# host_xip_secure register map
Vendor: Texas Instruments
Peripheral module from a debugger description file (folder CC35X1).
Registers are 32-bit, access per field, reset 0x0 unless marked. A register's access mark holds for its fields unless they carry their own. Offsets are as the file gives them; lines under a group give offsets from that group; [hi:lo] are bit positions; {n}, {i} and the like mark numbered series; 'fields as' and 'values as' point back to an identical list; <NAME> marks a mode.

## host_xip_secure
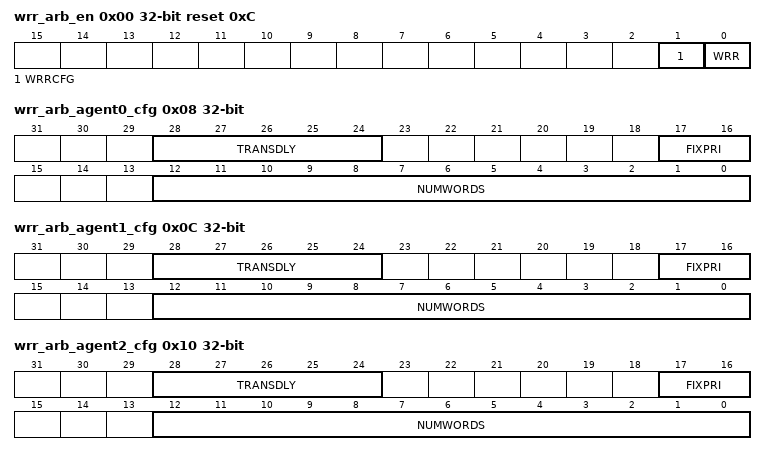
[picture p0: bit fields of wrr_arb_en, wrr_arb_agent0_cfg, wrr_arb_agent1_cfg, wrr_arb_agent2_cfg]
0x00 wrr_arb_en reset 0xC (reset mask 0xFFFFFFFC) — WRR Arbiter Enable
  [1] WRRCFG rw — WRR ARB POLICY RR: 0 - Fixed Priority 1 - Round Robin (Default)
  [0] WRR rw — 0 - Disabled, use SIE-200 arbitration logic. 1 - Enable, use wrapper arbitration logic.
0x08 wrr_arb_agent0_cfg reset not defined — WRR Arbiter - Agent 0 Configuration
  [28:24] TRANSDLY rw — Number of cycle before starting to serve next agent in line. Up to 32 cycles.
  [17:16] FIXPRI rw — For Fixed Priority: 0 - Highest. 1 - Medium. 2 - Lowest (default).
  [12:0] NUMWORDS rw — Number of words to be served in each arbitration grant. Up to 8,192 words (32KB). Value must be > 0.
0x0C wrr_arb_agent1_cfg reset not defined — WRR Arbiter - Agent 1 Configuration
  [28:24] TRANSDLY rw — Number of cycle before starting to serve next agent in line. Up to 32 cycles.
  [17:16] FIXPRI rw — For Fixed Priority: 0 - Highest. 1 - Medium (default). 2 - Lowest.
  [12:0] NUMWORDS rw — Number of words to be served in each arbitration grant. Up to 8,192 words (32KB). Value must be > 0.
0x10 wrr_arb_agent2_cfg reset not defined — WRR Arbiter - Agent 2 Configuration
  [28:24] TRANSDLY rw — Number of cycle before starting to serve next agent in line. Up to 32 cycles.
  [17:16] FIXPRI rw — For Fixed Priority: 0 - Highest (default). 1 - Medium. 2 - Lowest.
  [12:0] NUMWORDS rw — Number of words to be served in each arbitration grant. Up to 8,192 words (32KB). Value must be > 0.
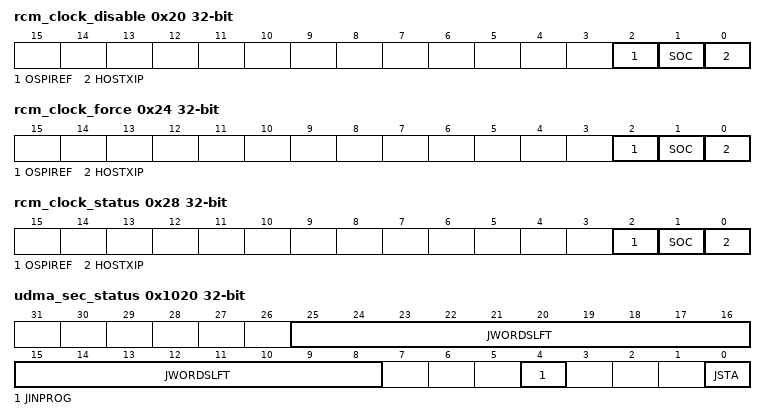
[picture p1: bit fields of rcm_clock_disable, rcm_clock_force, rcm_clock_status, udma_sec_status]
0x20 rcm_clock_disable — Disable clocks using HOST_XIP_RCM Module
  [2] OSPIREF rw — OSPI REF CLK SW DISABLE: 1 - Clock is permanent blocked (not depended on clk_req input) 0 - (default) - Clock is not blocked, but gated with clk_req input port
  [1] SOC rw — SOC CLK SW DISABLE: 1 - Clock is permanent blocked (not depended on clk_req input) 0 - (default) - Clock is not blocked, but gated with clk_req input port
  [0] HOSTXIP rw — HOST_XIP CLK SW DISABLE: 1 - Clock is permanent blocked (not depended on clk_req input) 0 - (default) - Clock is not blocked, but gated with clk_req input port
0x24 rcm_clock_force — Force clocks using HOST_XIP_RCM Module
  [2] OSPIREF rw — OSPI REF CLK SW FORCE: 1 - Force clk (even if sw_disable_clk is 1 or clk_req is 0) 0 - Clock is not forced, but gated with clk_req input port
  [1] SOC rw — SOC CLK SW FORCE: 1 - Force clk (even if sw_disable_clk is 1 or clk_req is 0) 0 - Clock is not forced, but gated with clk_req input port
  [0] HOSTXIP rw — HOST_XIP CLK SW FORCE: 1 - Force clk (even if sw_disable_clk is 1 or clk_req is 0) 0 - Clock is not forced, but gated with clk_req input port
0x28 rcm_clock_status ro — (ICG) Clock Status from HOST_XIP_RCM Module
  [2] OSPIREF — 1 - Force clk (even if sw_disable_clk is 1 or clk_req is 0) 0 - Clock is not forced, but gated with clk_req input port
  [1] SOC — 1 - Force clk (even if sw_disable_clk is 1 or clk_req is 0) 0 - Clock is not forced, but gated with clk_req input port
  [0] HOSTXIP — 1 - Force clk (even if sw_disable_clk is 1 or clk_req is 0) 0 - Clock is not forced, but gated with clk_req input port
0x1000 udma_sec_src_addr_cfg rw — uDMA source address for secured read master. Must be Word aligned.
  [31:0] JSRCADDR — DMA SEC JOB SRC ADDR: Specifies source address for secured read master. Source address must comply with bit.26 to enable Sec/Non-Sec accesses, otherwise transactions will be blocked.
0x1004 udma_sec_dst_addr_cfg rw — uDMA destination address for secured write master. Must be Word aligned.
  [31:0] JDESTADDR — DMA SEC JOB DST ADDR: Specifies destination address for secured write master. Destination address must comply with bit.26 to enable Sec/Non-Sec accesses, otherwise transactions will be blocked.
0x1008 udma_sec_length_cfg — uDMA secured job Length
  [17:0] JLEN rw — DMA SEC JOB LENGTH: Resolution - 1 Word Maximum configurable job size - 1 Mega byte (256K Words). (Maximum available size in MEMSS is 1MB).
0x100C udma_sec_mode_cfg — uDMA Direction
  [0] JDIR rw — DMA SEC JOB MODE: 0 - Data movement from External memory to Internal memory. 1 - Data movement from Internal memory to External memory.
0x1010 udma_sec_start — uDMA secured job kick
  [0] JSTART wo — DMA SEC JOB START WRCL: Start command for uDMA to start working on secured configured job.
0x1014 udma_sec_clear — uDMA secured job abort
  [0] JCLR wo — DMA SEC JOB CLEAR WRCL: Clear command for uDMA to stop working and clear configuration.
0x1020 udma_sec_status ro — uDMA secured Status bits
  [25:8] JWORDSLFT — DMA SEC JOB IRQ WORDS LEFT: number of words left in sec job when IRQ error raised and IRQ rdcl status value is not 2'd3
  [4] JINPROG — DMA SEC JOB IN PROGRESS: 1- sec job is currently in progress and being executed by uDMA
  [0] JSTA — DMA SEC JOB ACTIVE: Status bit to indicate that DMA is processing a secured job. When this bit is set, SW has written all the job parameters and also provided a start_pulse to HW, and cannot change job parameters without clear_pulse. Job will wait to be executed (indicated by job_in_progress)
0x1024 udma_sec_irq_status ro — uDMA secured IRQ Status bits
  [1:0] JIRQSTA — Status vector for IRQ indication for secured DMA IRQ: 2'd0 - DMA done. 2'd1 - DMA bus error occurred. check SEC_STATUS in order to recovers 2'd2 - DMA security error occurred. *** (==1'b0) - No DMA security error can occur in Security Channel ***
0x2000 udma_nonsec_src_addr_cfg rw — uDMA source address for non-secured read master. Must be Word aligned.
  [31:0] JSRCADDR — DMA NONSEC JOB SRC ADDR: Specifies source address for non-secured read master. Source address must comply with bit.26 to enable Sec/Non-Sec accesses, otherwise transactions will be blocked. In case using SAU to define secured memory region 'inside' the non-secured, this channel will allow this.
0x2004 udma_nonsec_dst_addr_cfg rw — uDMA destination address for non-secured write master. Must be Word aligned.
  [31:0] JDESTADDR — DMA NONSEC JOB DST ADDR: Specifies destination address for non-secured write master. Destination address must comply with bit.26 to enable Sec/Non-Sec accesses, otherwise transactions will be blocked. In case using SAU to define secured memory region 'inside' the non-secured, this channel will allow this.
0x2008 udma_nonsec_length_cfg — uDMA non-secured job Length
  [17:0] JLEN rw — DMA NONSEC JOB LENGTH: Resolution - 1 Word Maximum configurable job size - 1 Mega byte (256K Words). (Maximum available size in MEMSS is 1MB).
0x200C udma_nonsec_mode_cfg — uDMA Direction
  [0] JDIR rw — DMA NONSEC JOB MODE: 0 - Data movement from External memory to Internal memory. 1 - Data movement from Internal memory to External memory.
0x2010 udma_nonsec_start — uDMA non-secured job kick
  [0] JSTART wo — DMA NONSEC JOB START WRCL: Start command for uDMA to start working on non-secured configured job.
0x2014 udma_nonsec_clear — uDMA non-secured job abort
  [0] JCLR wo — DMA NONSEC JOB CLEAR WRCL: Clear command for uDMA to stop working and clear configuration.
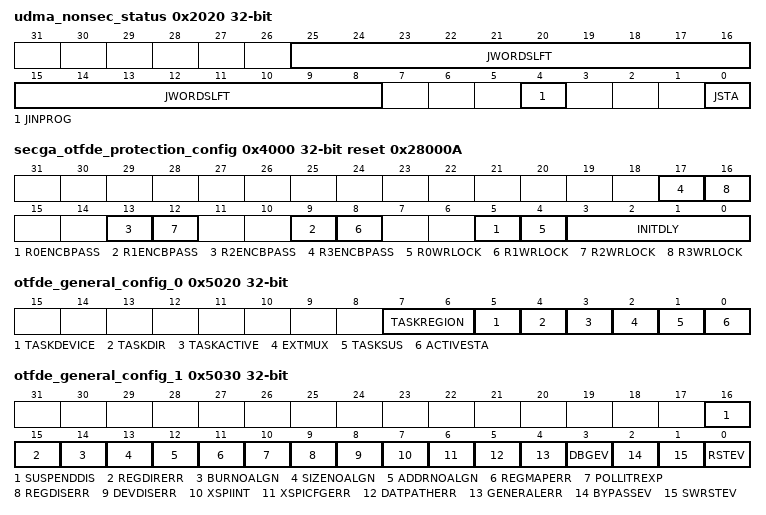
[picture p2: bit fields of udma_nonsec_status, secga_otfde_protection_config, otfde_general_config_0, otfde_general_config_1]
0x2020 udma_nonsec_status ro — uDMA non-secured Status bits
  [25:8] JWORDSLFT — DMA NONSEC JOB IRQ WORDS LEFT: number of words left in nonsec job when IRQ error raised and IRQ rdcl status value is not 2'd3
  [4] JINPROG — DMA NONSEC JOB IN PROGRESS: 1- nonsec job is currently in progress and being executed by uDMA
  [0] JSTA — DMA NONSEC JOB ACTIVE: Status bit to indicate that DMA is processing a non-secured job. When this bit is set, SW has written all the job parameters and also provided a start_pulse to HW, and cannot change job parameters without clear_pulse. Job will wait to be executed (indicated by job_in_progress)
0x2024 udma_nonsec_irq_status ro — uDMA non-secured IRQ Status bits
  [1:0] JIRQSTA — Status vector for IRQ indication for non-secured DMA IRQ: 2'd0 - DMA done. 2'd1 - DMA bus error occurred. check NONSEC_STATUS in order to recovers 2'd2 - DMA security error occurred.
0x3000 otfde_cfg_ospi rw — For Load/Read xSPI config job in OTFDE memory
  [31:0] WDATACFG — OTFDE CFG OSPI 81FC WR MEM xSPI config Memory wr/rd access (under OTFDE module)
0x4000 secga_otfde_protection_config reset 0x28000A (reset mask 0xFFFC000F) — SECGA OTFDE PROTECTION CONFIG: General OTFDE protection Configurations
  [4n+5] R{n}ENCBPASS rw (n=0..3) — OTFDE REGION {n} ENC DEC BYPASS: Encrypt Decrypt or Bypass transactions for region {n} 0- Enable bypass and no enc dec 1- Disable bypass and use enc dec
  [4n+4] R{n}WRLOCK rw (n=0..3) — OTFDE REGION {n} WRITE LOCK EN: Locks the ability to write into Region {n} registers 0- Lock Disabled 1- Lock Enabled
  [3:0] INITDLY rw — OTFDE INITIAL DELAY: 0-15 160MHz cycles of initial delay of the first transaction of a task must configure value greater than 10 (0xa)
0x4004 secga_region_0_key_0 rw — Region 0 key word 0
  [31:0] KEY0 — AES encryption Key LSBs
0x4008 secga_region_0_key_1 rw — Region 0 key word 1
  [31:0] KEY1 — AES encryption Key
0x400C secga_region_0_key_2 rw — Region 0 key word 2
  [31:0] KEY2 — AES encryption Key
0x4010 secga_region_0_key_3 rw — Region 0 key word 3
  [31:0] KEY3 — AES encryption Key MSBs
0x4014 secga_region_0_nonce_0 rw — Region 0 nonce word 0
  [31:0] NONCE0 — Nonce (IV)
0x4018 secga_region_0_nonce_1 rw — Region 0 nonce word 1
  [31:0] NONCE1 — Nonce (IV)
{0x4000+0x20*i} secga_region_{i}_key_0 rw (i=1..3) — Region {i} key word 0
  [31:0] KEY0 — AES encryption Key LSBs
0x4024 secga_region_1_key_1 rw — Region 1 key word 1
  [31:0] KEY1 — AES encryption Key
0x4028 secga_region_1_key_2 rw — Region 1 key word 2
  [31:0] KEY2 — AES encryption Key
0x402C secga_region_1_key_3 rw — Region 1 key word 3
  [31:0] KEY3 — AES encryption Key MSBs
{0x4010+0x20*i} secga_region_{i}_nonce_0 rw (i=1..3) — Region {i} nonce word 0
  [31:0] NONCE0 — Nonce (IV)
{0x4014+0x20*i} secga_region_{i}_nonce_1 rw (i=1..3) — Region {i} nonce word 1
  [31:0] NONCE1 — Nonce (IV)
0x4044 secga_region_2_key_1 rw — Region 1 key word 1
  [31:0] KEY1 — AES encryption Key
0x4048 secga_region_2_key_2 rw — Region 1 key word 2
  [31:0] KEY2 — AES encryption Key
0x404C secga_region_2_key_3 rw — Region 1 key word 3
  [31:0] KEY3 — AES encryption Key MSBs
0x4064 secga_region_3_key_1 rw — Region 3 key word 1
  [31:0] KEY1 — AES encryption Key
0x4068 secga_region_3_key_2 rw — Region 3 key word 2
  [31:0] KEY2 — AES encryption Key
0x406C secga_region_3_key_3 rw — Region 3 key word 3
  [31:0] KEY3 — AES encryption Key MSBs
0x5000 otfde_enable_config — Pulse signaled by SW to enable OTFDE and start handling incoming tasks
  [0] ENREQ wo — OTFDE SW ENABLE REQ WRCL: Pulse signaled by SW to enable OTFDE and start handling incoming tasks
0x5004 otfde_disable_config — Pulse signaled by SW to disable OTFDE and stop handling incoming task and erase all task related data
  [0] DISREQ wo — OTFDE SW DISABLE REQ WRCL: Pulse signaled by SW to disable OTFDE and stop handling incoming task and erase all task related data
0x5008 otfde_suspend_config — Pulse signaled by SW to suspend OTFDE task and hold task related data
  [0] SUSPENDREQ wo — OTFDE SW SUSPEND TASK REQ WRCL: Pulse signaled by SW to suspend OTFDE task and hold task related data
0x500C otfde_resume_config — Pulse signaled by SW to resume OTFDE suspended task
  [0] RESUMEREQ wo — OTFDE SW RESUME TASK REQ WRCL: Pulse signaled by SW to resume OTFDE suspended task
0x5010 otfde_soft_reset_config — Pulse signaled by SW to soft reset OTFDE engine and fifo and move to active idle
  [0] RSTREQ wo — OTFDE SW SOFT RESET REQ WRCL: 1- Soft Reset request pulse
0x5020 otfde_general_config_0 ro — OTFDE status
  [7:6] TASKREGION — OTFDE ACTIVE TASK REGION: 0- Region 0 active task 1- Region 1 active task 2- Region 2 active task 3- Region 3 active task value is valid only if OTFDE_ACTIVE or OTFDE_TASK_SUSPENDED are set
  [5] TASKDEVICE — OTFDE ACTIVE TASK DEVICE: 0- Device 0 active task 1- Device 1 active task value is valid only if OTFDE_ACTIVE or OTFDE_TASK_SUSPENDED are set
  [4] TASKDIR — OTFDE ACTIVE TASK TYPE: 0- Active read task 1- Active write task value is valid only if OTFDE_ACTIVE or OTFDE_TASK_SUSPENDED are set
  [3] TASKACTIVE — OTFDE ACTIVE TASK VALID: 0- No task is being handled, 1- A task is being handled, note: decide if OTFDE is active or suspended using OTFDE_ACTIVE and OTFDE_TASK_SUSPENDED
  [2] EXTMUX — OTFDE SELECT EXTERNAL MUX: 0- External Muxes bypassing OTFDE allowing System/ SW access to xspi 1- External Muxes are controlled by OTFDE which is Active and has access to xspi
  [1] TASKSUS — OTFDE TASK SUSPENDED 1- OTFDE is in task suspended mode 0- OTFDE is either active or disabled (IF OTFDE_ACTIVE is also de-asserted then OTFDE is disabled)
  [0] ACTIVESTA — OTFDE ACTIVE: 0- OTFDE is disabled IF OTFDE_TASK_SUSPENDED is also de-asserted 1- OTFDE is active
0x5030 otfde_general_config_1 ro — Event indication
  [16] SUSPENDDIS — OTFDE SW SUSPEND REQ WHILE DISABLED RDCL: 0 - Disable 1- Set Indication indication that SW requested suspend while OTFDE is disabled
  [15] REGDIRERR — OTFDE REGION READ WRITE DEF VIOLATION RDCL: 0 - Disable 1- Set Indication Indication that a transaction type was not allowed according to region definitions
  [14] BURNOALGN — OTFDE TRANS BURST NOT 32 BIT VIOLATION RDCL: 0 - Disable 1- Set Indication Indication that a transaction burst was not non-seq
  [13] SIZENOALGN — OTFDE TRANS SIZE NOT 32 BIT VIOLATION RDCL: 0 - Disable 1- Set Indication Indication that a transaction size was not 32 bit
  [12] ADDRNOALGN — OTFDE TRANS ADDRESS NOT 32 BIT VIOLATION RDCL: 0 - Disable 1- Set Indication Indication that a transaction address was not 32 bit aligned
  [11] REGMAPERR — OTFDE TRANS MULTIPLE REGIONS MAPPED ERROR RDCL: 0 - Disable 1- Set Indication Indication that a transaction was mapped into more than one region
  [10] POLLITREXP — OTFDE TRANS XSPI POLLING ITR EXPIRED RDCL: 0 - Disable 1- Set Indication Polling Request iterations expired
  [9] REGDISERR — OTFDE TRANS REGION DISABLED ERROR RDCL: 0 - Disable 1- Set Indication indication that the current transaction is into a disabled region
  [8] DEVDISERR — OTFDE TRANS DEVICE DISABLED ERROR RDCL: 0 - Disable 1- Set Indication indication that the current transaction is into a disabled device
  [7] XSPIINT — OTFDE XSPI SERVICE INTERRUPT INDICATION RDCL: 0 - Disable 1- Set Indication indication that service interruption criteria was triggered
  [6] XSPICFGERR — OTFDE XSPI CNFG PATH ERROR RDCL: 0 - Disable 1- Set Indication xSPI error on the config path to OTFDE
  [5] DATPATHERR — OTFDE XSPI DATA PATH ERROR_RDCL: 0 - Disable 1- Set Indication xSPI error on the data path to OTFDE
  [4] GENERALERR — OTFDE GENERAL ERROR RDCL: 0 - Disable 1- Set Indication General error event indication
  [3] DBGEV — 0 - Disable 1- Set Indication OTFDE entered or exited debug mode
  [2] BYPASSEV — OTFDE BYPASS MODE CHANGE EVENT RDCL: 0 - Disable 1- Set Indication OTFDE entered or exited bypass mode between suspend and resume states
  [1] SWRSTEV — OTFDE SOFT RESET EVENT RDCL: 0 - Disable 1- Set Indication OTFDE Soft reset completion event indication
  [0] RSTEV — OTFDE RESET EVENT RDCL: 0 - Disable 1- Set Indication OTFDE Hard reset or Disable request completion event indication
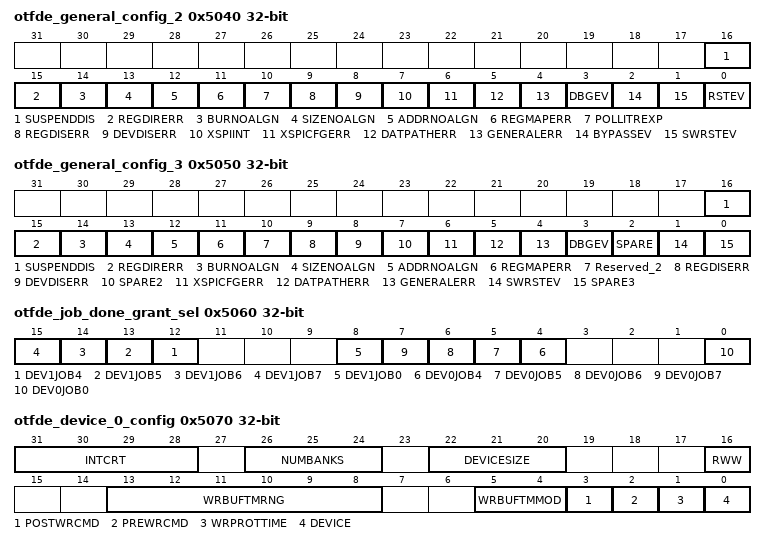
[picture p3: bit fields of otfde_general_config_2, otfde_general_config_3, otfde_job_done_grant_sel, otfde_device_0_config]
0x5040 otfde_general_config_2 reset not defined — Event Masked
  [16] SUSPENDDIS rw — OTFDE SUSPEND WHILE DISABLED MASK: 0- Masked 1- Enabled Enable / Mask SW requested suspend while OTFDE is disabled indication
  [15] REGDIRERR rw — OTFDE REGION READ WRITE DEF MASK: 0- Masked 1- Enabled Enable / Mask transaction type was not allowed according to region definitions
  [14] BURNOALGN rw — OTFDE TRANS BURST NOT 32 BIT MASK: 0- Masked 1- Enabled Enable / Mask transaction burst was not non-seq indication
  [13] SIZENOALGN rw — OTFDE TRANS SIZE NOT 32 BIT MASK: 0- Masked 1- Enabled Enable / Mask transaction size was not 32 bit indication
  [12] ADDRNOALGN rw — OTFDE TRANS ADDRESS NOT 32 BIT MASK: 0- Masked 1- Enabled Enable / Mask transaction address was not 32 bit aligned indication
  [11] REGMAPERR rw — OTFDE TRANS MULTIPLE REGIONS MAPPED MASK: 0- Masked 1- Enabled Enable / Mask transaction was mapped into more than one region indication
  [10] POLLITREXP rw — OTFDE XSPI POLLING ITR EXPIRED MASK: 0- Masked 1- Enabled Polling requests iterations expired
  [9] REGDISERR rw — OTFDE TRANS REGION DISABLED MASK: 0- Masked 1- Enabled Enable / Mask transaction into a disabled region event indication
  [8] DEVDISERR rw — OTFDE TRANS DEVICE DISABLED MASK: 0- Masked 1- Enabled Enable / Mask transaction into a disabled device event indication
  [7] XSPIINT rw — OTFDE XSPI SERVICE INTERRUPT MASK: 0- Masked 1- Enabled Enable / Mask xSPI service interrupt criteria event indication
  [6] XSPICFGERR rw — 0- Masked 1- Enabled Enable / Mask xSPI config path related errors signaled to OTFDE
  [5] DATPATHERR rw — OTFDE XSPI DATA PATH MASK: 0- Masked 1- Enabled Enable / Mask xSPI data path related errors signaled to OTFDE
  [4] GENERALERR rw — OTFDE GENERAL MASK: 0- Masked 1- Enabled Enable / Mask general error event
  [3] DBGEV ro — 0- Masked 1- Enabled Enable / Mask debug mode change completion
  [2] BYPASSEV rw — OTFDE BYPASS MODE CHANGE MASK: 0- Masked 1- Enabled Enable / Mask bypass mode change between suspend and resume completion event
  [1] SWRSTEV rw — OTFDE SOFT RESET MASK: 0- Masked 1- Enabled Enable / Mask soft reset completion event
  [0] RSTEV rw — OTFDE RESET MASK: 0- Masked 1- Enabled Enable / Mask hard reset completion event
0x5050 otfde_general_config_3 reset not defined — Event IRQ next state
  [16] SUSPENDDIS rw — OTFDE SUSPEND WHILE DISABLED NS: 0- Disable 1- N/A Decision of next state for SW requested suspend while OTFDE is disabled
  [15] REGDIRERR rw — OTFDE REGION READ WRITE VIOLATION NS: 0- Disable 1- Active Idle Decision of next state for transaction type was not allowed according to region definitions
  [14] BURNOALGN rw — OTFDE TRANS BURST NOT 32 BIT NS: 0- Disable 1- Active Idle Decision of next state for transaction burst was not non-seq indication
  [13] SIZENOALGN rw — OTFDE TRANS SIZE NOT 32 BIT NS: 0- Disable 1- Active Idle Decision of next state for transaction size was not 32 bit indication
  [12] ADDRNOALGN rw — OTFDE TRANS ADDRESS NOT 32 BIT NS: 0- Disable 1- Active Idle Decision of next state for transaction address was not 32 bit aligned indication
  [11] REGMAPERR rw — OTFDE TRANS MULTIPLE REGIONS MAPPED NS: 0- Disable 1- N/A Decision of next state for transaction was mapped into more than one region
  [10] Reserved_2 ro — 0- Disable 1- N/A Decision of next state for General region configuration error event indication
  [9] REGDISERR rw — OTFDE TRANS REGION DISABLED NS: 0- Disable 1- Active Idle Decision of next state for transaction into a disabled region event indication
  [8] DEVDISERR rw — OTFDE TRANS DEVICE DISABLED NS: 0- Disable 1- Active Idle Decision of next state for transaction into a disabled device event indication
  [7] SPARE2 rw — Spare register - unconnected in RTL.
  [6] XSPICFGERR rw — OTFDE XSPI CNFG PATH ERROR NS: 0- Disable 1- Active Idle Decision of next state for xSPI config path related errors signaled to OTFDE
  [5] DATPATHERR rw — OTFDE XSPI DATA PATH ERROR NS: 0- Disable 1- Active Idle Decision of next state for xSPI data path related errors signaled to OTFDE
  [4] GENERALERR rw — OTFDE GENERAL ERROR NS: 0- Disable 1- Active Idle Decision of next state for general error event
  [3] DBGEV ro — 0- Disable 1- Active Idle Decision of next state for debug mode change completion
  [2] SPARE rw — Spare register - unconnected in RTL. Used in ECO for PG1. Problem Statement In DDR 80MHz mode RD cmd, Seen in QPI (Octal not yet checked) the xSPI IP stop driving the data to soon violating Ext Mem hold requirement (~0.5ns v. up to ~2-3ns requirement for most vendors) Suggested Fix extend IO data drive by additional logic at IP for read commands in the DDR 80MHz mode
  [1] SWRSTEV rw — OTFDE SOFT RESET NS: 0- Disable 1- Active Idle Decision of next state for soft reset completion event
  [0] SPARE3 rw — Spare register - unconnected in RTL.
0x5060 otfde_job_done_grant_sel — set of controller non STIG configurations
  [n+8] DEV1JOB{n} rw (n=4..7) — Used when the access address does not match any region 0- Reject not mapped address access 1- Bypass not mapped address access (address is forwarded as is to xspi)
  [8] DEV1JOB0 rw — Used when the access address does not match any region 0- Reject not mapped address access 1- Bypass not mapped address access (address is forwarded as is to xspi)
  [n] DEV0JOB{n} rw (n=4..7) — Used when the access address does not match any region 0- Reject not mapped address access 1- Bypass not mapped address access (address is forwarded as is to xspi)
  [0] DEV0JOB0 rw — Used when the access address does not match any region 0- Reject not mapped address access 1- Bypass not mapped address access (address is forwarded as is to xspi)
0x5070 otfde_device_0_config reset not defined — Device 0 parameters
  [31:28] INTCRT rw — OTFDE DEVICE 0 SERVICE INTERRUPT CRITERIA: 0- No service interruption criteria. any other value is in 160MHz cycles between two transactions towards xSPI
  [26:24] NUMBANKS rw — OTFDE DEVICE 0 NUMBER OF BANKS: 000 - 1 Bank 001 - 2 Banks 010 - 4 Banks 011 - 8 Banks 100 - 16 Banks
  [22:20] DEVICESIZE rw — OTFDE DEVICE 0 SIZE: 000 - 2 MByte 001 - 4 MByte 010 - 8 MByte 011 - 16 MByte 100 - 32 MByte 101 - 64 MByte
  [16] RWW rw — OTFDE DEVICE 0 RWW EN: 0- Read while Write is disabled 1- Read while Write is Enabled
  [13:8] WRBUFTMRNG rw — OTFDE DEVICE 0 WRITE BUFFER TIMER RANGE: range is 0 - 63 multiplied by Mode resolution mode0: timer res is 16usec, timer range is 16-1024usec mode1: timer res is 32usec, timer range is 32-2048usec mode2: timer res is 64usec, timer range is 64-4192usec mode3: timer res is 256usec, timer range is 256-16384usec
  [5:4] WRBUFTMMOD rw — OTFDE DEVICE 0 WRITE BUFFER TIMER MODE: 00- mode0 is 16usec resolution 01- mode1 is 32usec resolution 10- mode2 is 64usec resolution 11- mode3 is 256usec resolution
  [3] POSTWRCMD rw — OTFDE DEVICE 0 ISSUE POST WRITE CMD: Issue a Post Write command after the write task ended 0- Do not issue POST WR CMD 1- Issue POST WR CMD after every write task
  [2] PREWRCMD rw — OTFDE DEVICE 0 ISSUE PRE WRITE CMD: Issue a Pre Write command before the next write task 0- Do not issue PRE WR CMD 1- Issue PRE WR CMD before every write task
  [1] WRPROTTIME rw — OTFDE DEVICE 0 WRITE PROTECTION TIMER EN: Set the write protection timer after a write task 0- Write protection timer is disabled 1- Write protection timer is enabled
  [0] DEVICE rw — OTFDE DEVICE 0 ENABLED: Device enabled (and all the device parameters were checked in SW) 0- Device Disabled 1- Device Enabled
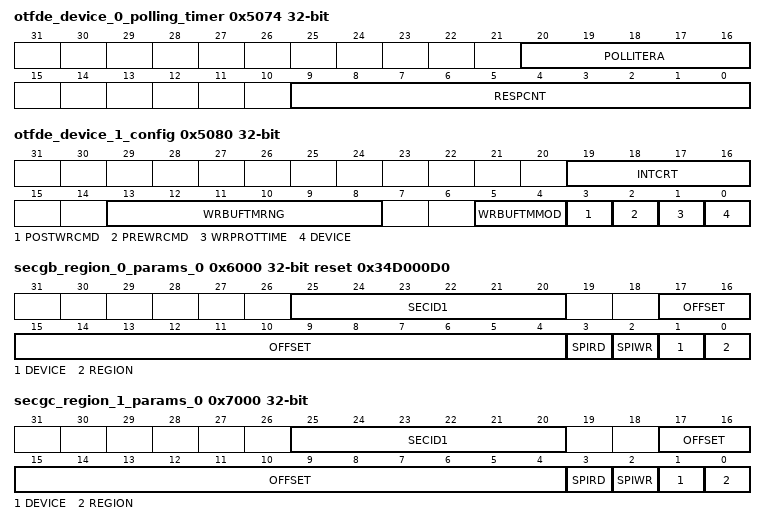
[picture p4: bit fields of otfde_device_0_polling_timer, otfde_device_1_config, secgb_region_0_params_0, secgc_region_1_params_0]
0x5074 otfde_device_0_polling_timer reset not defined — Device 0 polling timer parameters
  [20:16] POLLITERA rw — This value holds the number of additional iterations before polling process is considered complete range : 0-31 iterations Translating into total polling request iterations: min 1 and max 32
  [9:0] RESPCNT rw — This value holds the amount of time in us between each polling iteration sent to xspi control range : 1us-1023us value zero is NA
0x5080 otfde_device_1_config — Device 1 parameters
  [19:16] INTCRT rw — OTFDE DEVICE 1 SERVICE INTERRUPT CRITERIA: 0- No service interruption criteria. any other value is in 160MHz cycles between two transactions towards xSPI
  [13:8] WRBUFTMRNG rw — OTFDE DEVICE 1 WRITE BUFFER TIMER RANGE: range is 0 - 63 multiplied by Mode resolution mode0: timer res is 16usec, timer range is 16-1024usec mode1: timer res is 32usec, timer range is 32-2048usec mode2: timer res is 64usec, timer range is 64-4192usec mode3: timer res is 256usec, timer range is 256-16384usec
  [5:4] WRBUFTMMOD rw — OTFDE DEVICE 1 WRITE BUFFER TIMER MODE: 00- mode0 is 16usec resolution 01- mode1 is 32usec resolution 10- mode2 is 64usec resolution 11- mode3 is 256usec resolution
  [3] POSTWRCMD rw — OTFDE DEVICE 1 ISSUE POST WRITE CMD: Issue a Post Write command after the write task ended 0- Do not issue POST WR CMD 1- Issue POST WR CMD after every write task
  [2] PREWRCMD rw — OTFDE DEVICE 1 ISSUE PRE WRITE CMD: Issue a Pre Write command before the next write task 0- Do not issue PRE WR CMD 1- Issue PRE WR CMD before every write task
  [1] WRPROTTIME rw — OTFDE DEVICE 1 WRITE PROTECTION TIMER EN: Set the write protection timer after a write task 0- Write protection timer is disabled 1- Write protection timer is enabled
  [0] DEVICE rw — OTFDE DEVICE 1 ENABLED: Device enabled (and all the device parameters were checked in SW) 0 - Device Disabled 1- Device Enabled
0x5090 otfde_global_watchdog reset 0x2D — Global watchdog timer counting before raising IRQ
  [2:0] VAL rw — Watchdog timer in ms Timer pops watchdog IRQ in case a process within OTFDE crosses the required time range 0-7 translated to up to 7ms value 0 is NA
0x6000 secgb_region_0_params_0 reset 0x34D000D0 (reset mask 0xFFF3FFF0) — region 0 parameters config 0
  [25:20] SECID1 rw — 6 MSB bits of ID+COUNTER field (out of 38bits)
  [17:4] OFFSET rw — Device related address offset
  [3] SPIRD rw — REGION 0 SPI READ ENABLE: 0- Cannot issue a SPI Read from this region 1- Can issue a SPI Read from this region
  [2] SPIWR rw — REGION 0 SPI WRITE ENABLE: 0- Cannot issue a SPI Write to this region 1- Can issue a SPI Write to this region
  [1] DEVICE rw — REGION 0 DEVICE ID: 0- Device_0 1- Device_1
  [0] REGION rw — REGION 0 ENABLED: 0- Disabled 1- Enabled Region enabled for incoming transactions
0x6004 secgb_region_0_params_1 reset 0x10000 — region 0 parameters config 1
  [19:0] STARTADDR rw — System start address
0x6008 secgb_region_0_params_2 reset 0x17FFF — region 0 parameters config 2
  [19:0] ENDADDR rw — System end address
0x600C secgb_region_0_params_3 rw — region 0 parameters config 3
  [31:0] SECID0 — 32 LSB bits of ID+COUNTER field (out of 38bits)
0x7000 secgc_region_1_params_0 — region 1 parameters config 0
  [25:20] SECID1 rw — 6 MSB bits of ID+COUNTER field (out of 38bits)
  [17:4] OFFSET rw — Device related address offset
  [3] SPIRD rw — REGION 1 SPI READ ENABLE: 0- Cannot issue a SPI Read from this region 1- Can issue a SPI Read from this region
  [2] SPIWR rw — REGION 1 SPI WRITE ENABLE: 0- Cannot issue a SPI Write to this region 1- Can issue a SPI Write to this region
  [1] DEVICE rw — REGION 1 DEVICE ID: 0- Device_0 1- Device_1
  [0] REGION rw — REGION 1 ENABLED: 0- Disabled 1- Enabled Region enabled for incoming transactions
0x7004 secgc_region_1_params_1 reset 0x100001 — region 1 parameters config 1
  [19:0] STARTADDR rw — System start address
0x7008 secgc_region_1_params_2 — region 1 parameters config 2
  [19:0] ENDADDR rw — System end address
0x700C secgc_region_1_params_3 rw — region 1 parameters config 3
  [31:0] SECID0 — 32 LSB bits of ID+COUNTER field (out of 38bits)
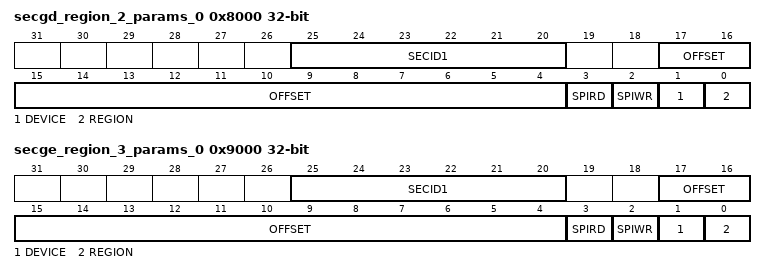
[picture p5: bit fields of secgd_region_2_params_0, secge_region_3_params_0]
0x8000 secgd_region_2_params_0 — region 2 parameters config 0
  [25:20] SECID1 rw — 6 MSB bits of ID+COUNTER field (out of 38bits)
  [17:4] OFFSET rw — Device related address offset
  [3] SPIRD rw — REGION 2 SPI READ ENABLE: 0- Cannot issue a SPI Read from this region 1- Can issue a SPI Read from this region
  [2] SPIWR rw — REGION 2 SPI WRITE ENABLE: 0- Cannot issue a SPI Write to this region 1- Can issue a SPI Write to this region
  [1] DEVICE rw — REGION 2 DEVICE ID: 0- Device_0 1- Device_1
  [0] REGION rw — REGION 2 ENABLED: 0- Disabled 1- Enabled Region enabled for incoming transactions
0x8004 secgd_region_2_params_1 reset 0x100001 — region 2 parameters config 1
  [19:0] STARTADDR rw — System start address
0x8008 secgd_region_2_params_2 — region 2 parameters config 2
  [19:0] ENDADDR rw — System end address
0x800C secgd_region_2_params_3 rw — region 2 parameters config 3
  [31:0] SECID0 — 32 LSB bits of ID+COUNTER field (out of 38bits)
0x9000 secge_region_3_params_0 — region 3 parameters config 0
  [25:20] SECID1 rw — 6 MSB bits of ID+COUNTER field (out of 38bits)
  [17:4] OFFSET rw — Device related address offset
  [3] SPIRD rw — REGION 3 SPI READ ENABLE: 0- Cannot issue a SPI Read from this region 1- Can issue a SPI Read from this region
  [2] SPIWR rw — REGION 3 SPI WRITE ENABLE: 0- Cannot issue a SPI Write to this region 1- Can issue a SPI Write to this region
  [1] DEVICE rw — REGION 3 DEVICE ID: 0- Device_0 1- Device_1
  [0] REGION rw — REGION 3 ENABLED: 0- Disabled 1- Enabled Region enabled for incoming transactions
0x9004 secge_region_3_params_1 reset 0x100001 — region 3 parameters config 1
  [19:0] STARTADDR rw — System start address
0x9008 secge_region_3_params_2 — region 3 parameters config 2
  [19:0] ENDADDR rw — System end address
0x900C secge_region_3_params_3 rw — region 3 parameters config 3
  [31:0] SECID0 — 32 LSB bits of ID+COUNTER field (out of 38bits)
